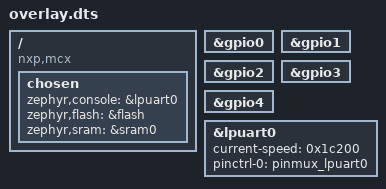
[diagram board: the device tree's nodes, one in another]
/ {
	compatible = "nxp,mcx", "nxp,mcxa156";
	chosen {
		zephyr,console = &lpuart0;
		zephyr,flash = &flash;
		zephyr,sram = &sram0;
	};
};
&gpio0{
	status = "okay";
};
&gpio1{
	status = "okay";
};
&gpio2{
	status = "okay";
};
&gpio3{
	status = "okay";
};
&gpio4{
	status = "okay";
};
&lpuart0{
	status = "okay";
	current-speed = < 0x1c200 >;
	pinctrl-0 = < &pinmux_lpuart0 >;
	pinctrl-names = "default";
};
